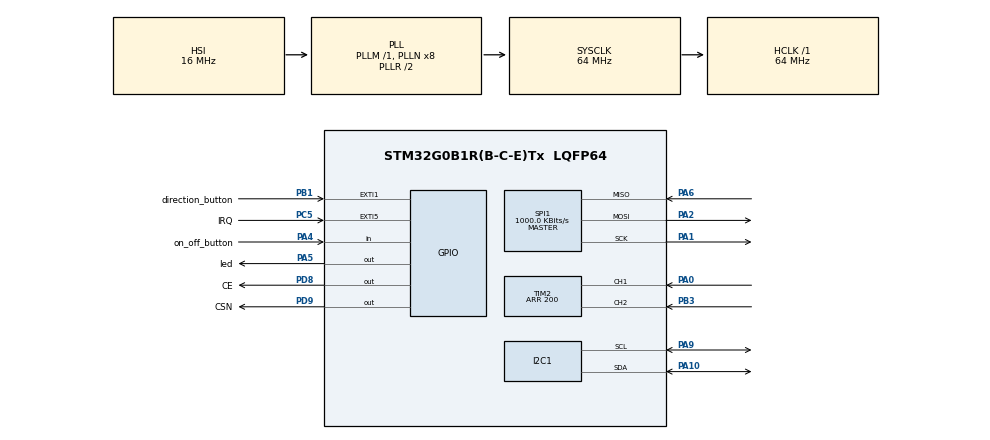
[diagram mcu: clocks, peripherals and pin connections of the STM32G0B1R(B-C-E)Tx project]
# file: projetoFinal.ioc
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I2C1.Timing=0x10707DBC
Mcu.Family=STM32G0
Mcu.Name=STM32G0B1R(B-C-E)Tx
Mcu.Package=LQFP64
NVIC.EXTI0_1_IRQn=true\:0\:0\:false\:false\:true\:true\:true
NVIC.EXTI4_15_IRQn=true\:0\:0\:false\:false\:true\:true\:true
NVIC.SPI1_IRQn=true\:0\:0\:false\:false\:true\:true\:true
NVIC.TIM2_IRQn=true\:0\:0\:false\:false\:true\:true\:true
PA0.Signal=S_TIM2_CH1_ETR
PA1.Mode=Full_Duplex_Master
PA1.Signal=SPI1_SCK
PA10.Mode=I2C
PA10.Signal=I2C1_SDA
PA13.Mode=Serial_Wire
PA13.Signal=SYS_SWDIO
PA14-BOOT0.Mode=Serial_Wire
PA14-BOOT0.Signal=SYS_SWCLK
PA2.Mode=Full_Duplex_Master
PA2.Signal=SPI1_MOSI
PA4.GPIO_Label=on_off_button
PA4.GPIO_PuPd=GPIO_PULLUP
PA4.Signal=GPIO_Input
PA5.GPIO_Label=led
PA5.Signal=GPIO_Output
PA6.Mode=Full_Duplex_Master
PA6.Signal=SPI1_MISO
PA9.Mode=I2C
PA9.Signal=I2C1_SCL
PB1.GPIO_Label=direction_button
PB1.GPIO_ModeDefaultEXTI=GPIO_MODE_IT_FALLING
PB1.Signal=GPXTI1
PB3.Signal=S_TIM2_CH2
PC14-OSC32_IN\ (PC14).Mode=LSE-External-Oscillator
PC14-OSC32_IN\ (PC14).Signal=RCC_OSC32_IN
PC15-OSC32_OUT\ (PC15).Mode=LSE-External-Oscillator
PC15-OSC32_OUT\ (PC15).Signal=RCC_OSC32_OUT
PC5.GPIO_Label=IRQ
PC5.Signal=GPXTI5
PD8.GPIO_Label=CE
PD8.GPIO_Speed=GPIO_SPEED_FREQ_VERY_HIGH
PD8.PinState=GPIO_PIN_SET
PD8.Signal=GPIO_Output
PD9.GPIO_Label=CSN
PD9.GPIO_Speed=GPIO_SPEED_FREQ_VERY_HIGH
PD9.Signal=GPIO_Output
PF0-OSC_IN\ (PF0).Mode=HSE-External-Oscillator
PF0-OSC_IN\ (PF0).Signal=RCC_OSC_IN
PF1-OSC_OUT\ (PF1).Mode=HSE-External-Oscillator
PF1-OSC_OUT\ (PF1).Signal=RCC_OSC_OUT
ProjectManager.HeapSize=0x200
ProjectManager.StackSize=0x400
ProjectManager.TargetToolchain=STM32CubeIDE
RCC.ADCFreq_Value=64000000
RCC.AHBFreq_Value=64000000
RCC.CortexFreq_Value=64000000
RCC.EXTERNAL_CLOCK_VALUE=48000
RCC.HCLKFreq_Value=64000000
RCC.HSE_VALUE=8000000
RCC.HSI48_VALUE=48000000
RCC.HSI_VALUE=16000000
RCC.SYSCLKFreq_VALUE=64000000
RCC.SYSCLKSource=RCC_SYSCLKSOURCE_PLLCLK
RCC.USBFreq_Value=48000000
RCC.VCOOutputFreq_Value=128000000
SH.S_TIM2_CH1_ETR.0=TIM2_CH1,Encoder_Interface
SH.S_TIM2_CH2.0=TIM2_CH2,Encoder_Interface
SPI1.BaudRatePrescaler=SPI_BAUDRATEPRESCALER_64
SPI1.CalculateBaudRate=1000.0 KBits/s
SPI1.Direction=SPI_DIRECTION_2LINES
SPI1.Mode=SPI_MODE_MASTER
SPI1.VirtualType=VM_MASTER
TIM2.EncoderMode=TIM_ENCODERMODE_TI12
TIM2.IC1Filter=0
TIM2.IC1Polarity=TIM_ICPOLARITY_FALLING
TIM2.IC2Filter=0
TIM2.IC2Polarity=TIM_ICPOLARITY_FALLING
TIM2.Period=200
VP_SYS_VS_DBSignals.Mode=DisableDeadBatterySignals
board=custom

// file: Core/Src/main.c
/* USER CODE BEGIN Header */
/**
  ******************************************************************************
  * @file           : main.c
  * @brief          : Main program body
  ******************************************************************************
  * @attention
  *
  * Copyright (c) 2022 STMicroelectronics.
  * All rights reserved.
  *
  * This software is licensed under terms that can be found in the LICENSE file
  * in the root directory of this software component.
  * If no LICENSE file comes with this software, it is provided AS-IS.
  *
  ******************************************************************************
  */
/* USER CODE END Header */
#include "main.h"
#include "i2c.h"
#include "spi.h"
#include "tim.h"
#include "gpio.h"

/* USER CODE BEGIN Includes */
#include <stdint.h>

#include "string.h"

#include "nrf24.h"

#include "transmit.h"

/* USER CODE END Includes */

void SystemClock_Config(void);

/* USER CODE BEGIN 0 */
//uint8_t data_array[4];
//uint8_t tx_address[5] = {0xE7,0xE7,0xE7,0xE7,0xE7}; //E7
//uint8_t rx_address[5] = {0xD7,0xD7,0xD7,0xD7,0xD7};

//void HAL_TIM_IC_CaptureCallback(TIM_HandleTypeDef *htim){
//	counter = __HAL_TIM_GET_COUNTER(htim);
//
//}
/* USER CODE END 0 */

int main(void)
{

  /* MCU Configuration--------------------------------------------------------*/

  /* Reset of all peripherals, Initializes the Flash interface and the Systick. */
  HAL_Init();

  /* Configure the system clock */
  SystemClock_Config();

  /* Initialize all configured peripherals */
  MX_GPIO_Init();
  MX_SPI1_Init();
  MX_TIM2_Init();
  MX_I2C1_Init();
  /* USER CODE BEGIN 2 */

  transmit_init();
  transmit_run();

  /* USER CODE END 2 */

  /* Infinite loop */
  /* USER CODE BEGIN WHILE */
  while (1)
  {
//	  HAL_GPIO_WritePin(led_GPIO_Port, led_Pin, GPIO_PIN_SET);
//	  data_array[0]++;
//	  nrf24_send(data_array);
//	  //nrf24_send(data_array);
//	  HAL_Delay(50);
//	  HAL_GPIO_WritePin(led_GPIO_Port, led_Pin, GPIO_PIN_RESET);
//
//	  HAL_Delay(1000);
    /* USER CODE END WHILE */

  }
}

void SystemClock_Config(void)
{
  RCC_OscInitTypeDef RCC_OscInitStruct = {0};
  RCC_ClkInitTypeDef RCC_ClkInitStruct = {0};

  /** Configure the main internal regulator output voltage
  */
  HAL_PWREx_ControlVoltageScaling(PWR_REGULATOR_VOLTAGE_SCALE1);
  /** Initializes the RCC Oscillators according to the specified parameters
  * in the RCC_OscInitTypeDef structure.
  */
  RCC_OscInitStruct.OscillatorType = RCC_OSCILLATORTYPE_HSI;
  RCC_OscInitStruct.HSIState = RCC_HSI_ON;
  RCC_OscInitStruct.HSIDiv = RCC_HSI_DIV1;
  RCC_OscInitStruct.HSICalibrationValue = RCC_HSICALIBRATION_DEFAULT;
  RCC_OscInitStruct.PLL.PLLState = RCC_PLL_ON;
  RCC_OscInitStruct.PLL.PLLSource = RCC_PLLSOURCE_HSI;
  RCC_OscInitStruct.PLL.PLLM = RCC_PLLM_DIV1;
  RCC_OscInitStruct.PLL.PLLN = 8;
  RCC_OscInitStruct.PLL.PLLP = RCC_PLLP_DIV2;
  RCC_OscInitStruct.PLL.PLLQ = RCC_PLLQ_DIV2;
  RCC_OscInitStruct.PLL.PLLR = RCC_PLLR_DIV2;
  if (HAL_RCC_OscConfig(&RCC_OscInitStruct) != HAL_OK)
  {
    Error_Handler();
  }
  /** Initializes the CPU, AHB and APB buses clocks
  */
  RCC_ClkInitStruct.ClockType = RCC_CLOCKTYPE_HCLK|RCC_CLOCKTYPE_SYSCLK
                              |RCC_CLOCKTYPE_PCLK1;
  RCC_ClkInitStruct.SYSCLKSource = RCC_SYSCLKSOURCE_PLLCLK;
  RCC_ClkInitStruct.AHBCLKDivider = RCC_SYSCLK_DIV1;
  RCC_ClkInitStruct.APB1CLKDivider = RCC_HCLK_DIV1;

  if (HAL_RCC_ClockConfig(&RCC_ClkInitStruct, FLASH_LATENCY_2) != HAL_OK)
  {
    Error_Handler();
  }
}

void Error_Handler(void)
{
  __disable_irq();
  while (1)
  {
  }
}
